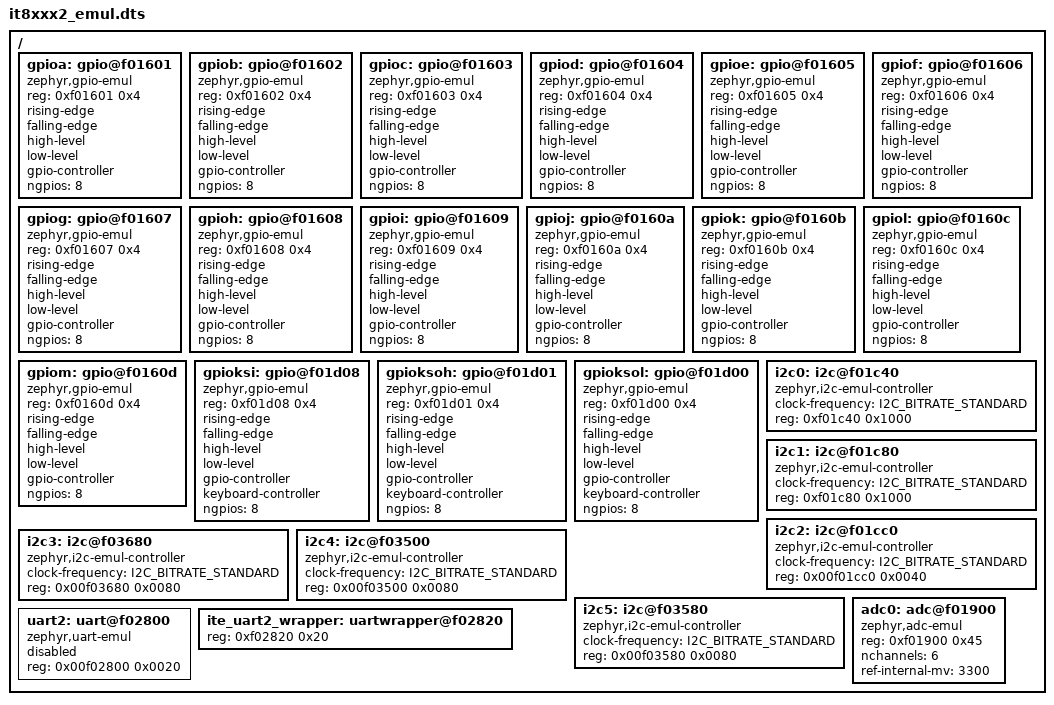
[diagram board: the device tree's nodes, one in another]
/* Copyright 2022 The ChromiumOS Authors
 * Use of this source code is governed by a BSD-style license that can be
 * found in the LICENSE file.
 */

/* Contains emulators for devices normally found on IT8xxx2 chips.
 * To use, include this file, then the board's gpio definitions.
 */

#include <dt-bindings/gpio_defines.h>
#include <dt-bindings/native-posix-gpio.h>

#define GPIO_VOLTAGE_1P8 NATIVE_POSIX_GPIO_VOLTAGE_1P8

/ {
	/* Delete conflicting native sim peripherals. */
	/delete-node/ adc;
	/delete-node/ i2c@100;

	gpioa: gpio@f01601 {
		status = "okay";
		compatible = "zephyr,gpio-emul";
		reg = <0xf01601 0x4>;
		rising-edge;
		falling-edge;
		high-level;
		low-level;
		gpio-controller;
		#gpio-cells = <2>;
		ngpios = <8>;
	};
	gpiob: gpio@f01602 {
		status = "okay";
		compatible = "zephyr,gpio-emul";
		reg = <0xf01602 0x4>;
		rising-edge;
		falling-edge;
		high-level;
		low-level;
		gpio-controller;
		#gpio-cells = <2>;
		ngpios = <8>;
	};
	gpioc: gpio@f01603 {
		status = "okay";
		compatible = "zephyr,gpio-emul";
		reg = <0xf01603 0x4>;
		rising-edge;
		falling-edge;
		high-level;
		low-level;
		gpio-controller;
		#gpio-cells = <2>;
		ngpios = <8>;
	};
	gpiod: gpio@f01604 {
		status = "okay";
		compatible = "zephyr,gpio-emul";
		reg = <0xf01604 0x4>;
		rising-edge;
		falling-edge;
		high-level;
		low-level;
		gpio-controller;
		#gpio-cells = <2>;
		ngpios = <8>;
	};
	gpioe: gpio@f01605 {
		status = "okay";
		compatible = "zephyr,gpio-emul";
		reg = <0xf01605 0x4>;
		rising-edge;
		falling-edge;
		high-level;
		low-level;
		gpio-controller;
		#gpio-cells = <2>;
		ngpios = <8>;
	};
	gpiof: gpio@f01606 {
		status = "okay";
		compatible = "zephyr,gpio-emul";
		reg = <0xf01606 0x4>;
		rising-edge;
		falling-edge;
		high-level;
		low-level;
		gpio-controller;
		#gpio-cells = <2>;
		ngpios = <8>;
	};
	gpiog: gpio@f01607 {
		status = "okay";
		compatible = "zephyr,gpio-emul";
		reg = <0xf01607 0x4>;
		rising-edge;
		falling-edge;
		high-level;
		low-level;
		gpio-controller;
		#gpio-cells = <2>;
		ngpios = <8>;
	};
	gpioh: gpio@f01608 {
		status = "okay";
		compatible = "zephyr,gpio-emul";
		reg = <0xf01608 0x4>;
		rising-edge;
		falling-edge;
		high-level;
		low-level;
		gpio-controller;
		#gpio-cells = <2>;
		ngpios = <8>;
	};
	gpioi: gpio@f01609 {
		status = "okay";
		compatible = "zephyr,gpio-emul";
		reg = <0xf01609 0x4>;
		rising-edge;
		falling-edge;
		high-level;
		low-level;
		gpio-controller;
		#gpio-cells = <2>;
		ngpios = <8>;
	};
	gpioj: gpio@f0160a {
		status = "okay";
		compatible = "zephyr,gpio-emul";
		reg = <0xf0160a 0x4>;
		rising-edge;
		falling-edge;
		high-level;
		low-level;
		gpio-controller;
		#gpio-cells = <2>;
		ngpios = <8>;
	};
	gpiok: gpio@f0160b {
		status = "okay";
		compatible = "zephyr,gpio-emul";
		reg = <0xf0160b 0x4>;
		rising-edge;
		falling-edge;
		high-level;
		low-level;
		gpio-controller;
		#gpio-cells = <2>;
		ngpios = <8>;
	};
	gpiol: gpio@f0160c {
		status = "okay";
		compatible = "zephyr,gpio-emul";
		reg = <0xf0160c 0x4>;
		rising-edge;
		falling-edge;
		high-level;
		low-level;
		gpio-controller;
		#gpio-cells = <2>;
		ngpios = <8>;
	};
	gpiom: gpio@f0160d {
		status = "okay";
		compatible = "zephyr,gpio-emul";
		reg = <0xf0160d 0x4>;
		rising-edge;
		falling-edge;
		high-level;
		low-level;
		gpio-controller;
		#gpio-cells = <2>;
		ngpios = <8>;
	};
	gpioksi: gpio@f01d08 {
		status = "okay";
		compatible = "zephyr,gpio-emul";
		reg = <0xf01d08 0x4>;
		rising-edge;
		falling-edge;
		high-level;
		low-level;
		gpio-controller;
		keyboard-controller;
		#gpio-cells = <2>;
		ngpios = <8>;
	};
	gpioksoh: gpio@f01d01 {
		status = "okay";
		compatible = "zephyr,gpio-emul";
		reg = <0xf01d01 0x4>;
		rising-edge;
		falling-edge;
		high-level;
		low-level;
		gpio-controller;
		keyboard-controller;
		#gpio-cells = <2>;
		ngpios = <8>;
	};
	gpioksol: gpio@f01d00 {
		status = "okay";
		compatible = "zephyr,gpio-emul";
		reg = <0xf01d00 0x4>;
		rising-edge;
		falling-edge;
		high-level;
		low-level;
		gpio-controller;
		keyboard-controller;
		#gpio-cells = <2>;
		ngpios = <8>;
	};

	i2c0: i2c@f01c40 {
		compatible = "zephyr,i2c-emul-controller";
		clock-frequency = <I2C_BITRATE_STANDARD>;
		#address-cells = <1>;
		#size-cells = <0>;
		reg = <0xf01c40 0x1000>;
	};

	i2c1: i2c@f01c80 {
		compatible = "zephyr,i2c-emul-controller";
		clock-frequency = <I2C_BITRATE_STANDARD>;
		#address-cells = <1>;
		#size-cells = <0>;
		reg = <0xf01c80 0x1000>;
	};

	i2c2: i2c@f01cc0 {
		compatible = "zephyr,i2c-emul-controller";
		clock-frequency = <I2C_BITRATE_STANDARD>;
		#address-cells = <1>;
		#size-cells = <0>;
		reg = <0x00f01cc0 0x0040>;
	};

	i2c3: i2c@f03680 {
		compatible = "zephyr,i2c-emul-controller";
		clock-frequency = <I2C_BITRATE_STANDARD>;
		#address-cells = <1>;
		#size-cells = <0>;
		reg = <0x00f03680 0x0080>;
	};

	i2c4: i2c@f03500 {
		compatible = "zephyr,i2c-emul-controller";
		clock-frequency = <I2C_BITRATE_STANDARD>;
		#address-cells = <1>;
		#size-cells = <0>;
		reg = <0x00f03500 0x0080>;
	};

	i2c5: i2c@f03580 {
		compatible = "zephyr,i2c-emul-controller";
		clock-frequency = <I2C_BITRATE_STANDARD>;
		#address-cells = <1>;
		#size-cells = <0>;
		reg = <0x00f03580 0x0080>;
	};

	adc0: adc@f01900 {
		compatible = "zephyr,adc-emul";
		reg = <0xf01900 0x45>;
		nchannels = <6>;
		ref-internal-mv = <3300>;
		#io-channel-cells = <1>;
	};

	uart2: uart@f02800 {
		compatible = "zephyr,uart-emul";
		reg = <0x00f02800 0x0020>;
		status = "disabled";
	};

	ite_uart2_wrapper: uartwrapper@f02820 {
		reg = <0xf02820 0x20>;
	};
};
